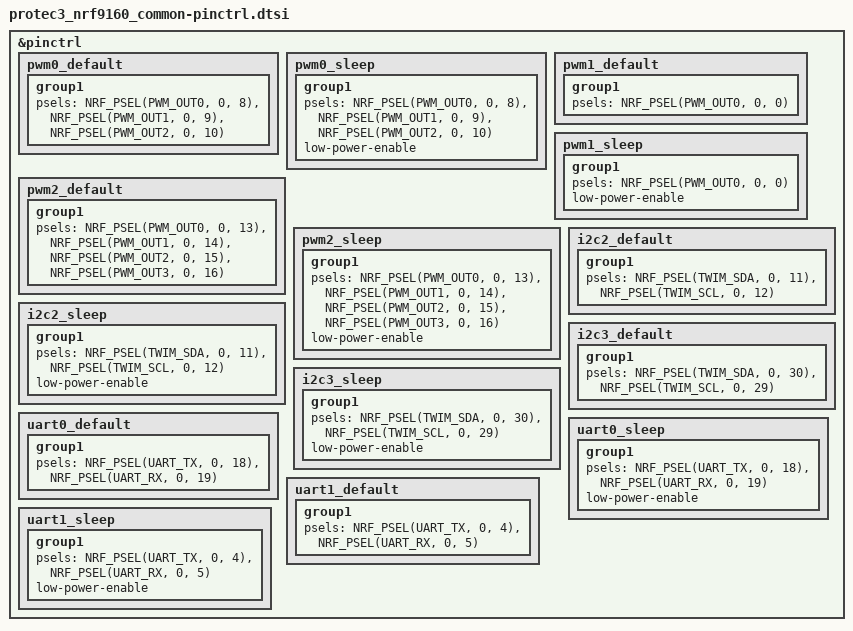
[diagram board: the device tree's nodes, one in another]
&pinctrl {
	pwm0_default: pwm0_default {
		group1 {
			psels = <NRF_PSEL(PWM_OUT0, 0, 8)>,
				<NRF_PSEL(PWM_OUT1, 0, 9)>,
				<NRF_PSEL(PWM_OUT2, 0, 10)>;
		};
	};

	pwm0_sleep: pwm0_sleep {
		group1 {
			psels = <NRF_PSEL(PWM_OUT0, 0, 8)>,
				<NRF_PSEL(PWM_OUT1, 0, 9)>,
				<NRF_PSEL(PWM_OUT2, 0, 10)>;
			low-power-enable;
		};
	};

	pwm1_default: pwm1_default {
		group1 {
			psels = <NRF_PSEL(PWM_OUT0, 0, 0)>;
		};
	};

	pwm1_sleep: pwm1_sleep {
		group1 {
			psels = <NRF_PSEL(PWM_OUT0, 0, 0)>;
			low-power-enable;
		};
	};

	pwm2_default: pwm2_default {
		group1 {
			psels = <NRF_PSEL(PWM_OUT0, 0, 13)>,
				<NRF_PSEL(PWM_OUT1, 0, 14)>,
				<NRF_PSEL(PWM_OUT2, 0, 15)>,
				<NRF_PSEL(PWM_OUT3, 0, 16)>;
		};
	};

	pwm2_sleep: pwm2_sleep {
		group1 {
			psels = <NRF_PSEL(PWM_OUT0, 0, 13)>,
				<NRF_PSEL(PWM_OUT1, 0, 14)>,
				<NRF_PSEL(PWM_OUT2, 0, 15)>,
				<NRF_PSEL(PWM_OUT3, 0, 16)>;
			low-power-enable;
		};
	};

	i2c2_default: i2c2_default {
		group1 {
			psels = <NRF_PSEL(TWIM_SDA, 0, 11)>,
				<NRF_PSEL(TWIM_SCL, 0, 12)>;
		};
	};

	i2c2_sleep: i2c2_sleep {
		group1 {
			psels = <NRF_PSEL(TWIM_SDA, 0, 11)>,
				<NRF_PSEL(TWIM_SCL, 0, 12)>;
			low-power-enable;
		};
	};

	i2c3_default: i2c3_default {
		group1 {
			psels = <NRF_PSEL(TWIM_SDA, 0, 30)>,
				<NRF_PSEL(TWIM_SCL, 0, 29)>;
		};
	};

	i2c3_sleep: i2c3_sleep {
		group1 {
			psels = <NRF_PSEL(TWIM_SDA, 0, 30)>,
				<NRF_PSEL(TWIM_SCL, 0, 29)>;
			low-power-enable;
		};
	};

	uart0_default: uart0_default {
		group1 {
			psels = <NRF_PSEL(UART_TX, 0, 18)>,
				<NRF_PSEL(UART_RX, 0, 19)>;
		};
	};

	uart0_sleep: uart0_sleep {
		group1 {
			psels = <NRF_PSEL(UART_TX, 0, 18)>,
				<NRF_PSEL(UART_RX, 0, 19)>;
			low-power-enable;
		};
	};

	uart1_default: uart1_default {
		group1 {
			psels = <NRF_PSEL(UART_TX, 0, 4)>,
				<NRF_PSEL(UART_RX, 0, 5)>;
		};
	};

	uart1_sleep: uart1_sleep {
		group1 {
			psels = <NRF_PSEL(UART_TX, 0, 4)>,
				<NRF_PSEL(UART_RX, 0, 5)>;
			low-power-enable;
		};
	};

};
